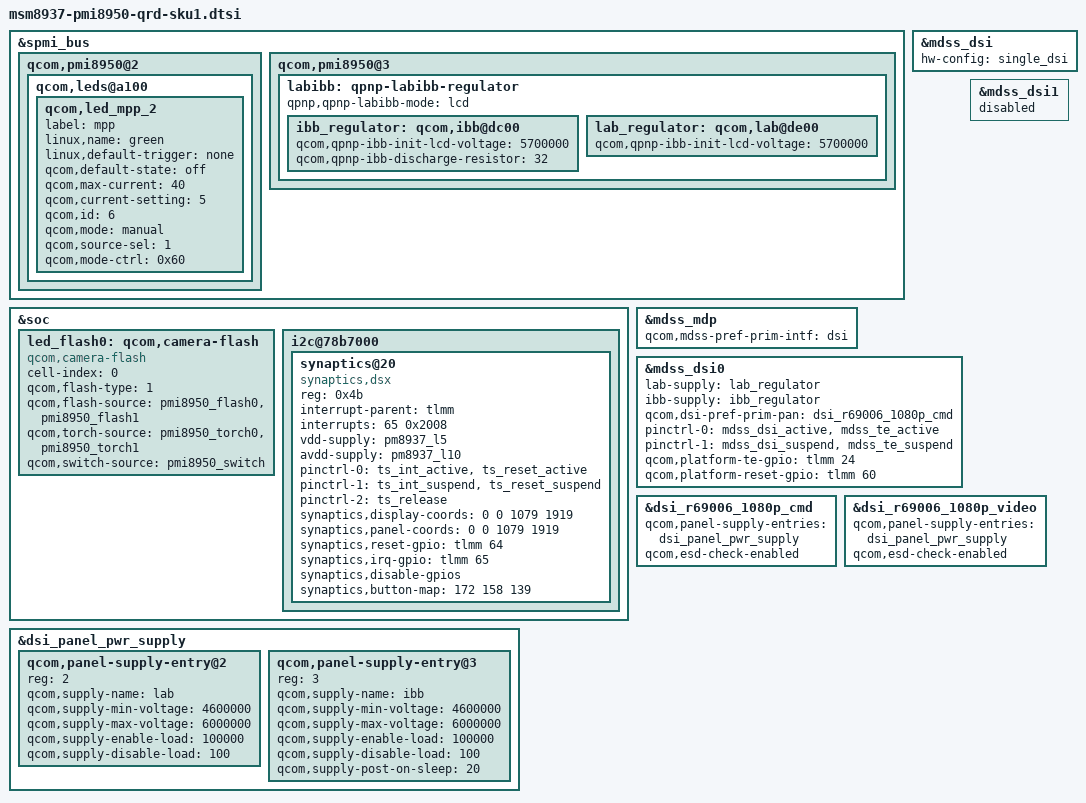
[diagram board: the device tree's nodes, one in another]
/*
 * Copyright (c) 2015, The Linux Foundation. All rights reserved.
 *
 * This program is free software; you can redistribute it and/or modify
 * it under the terms of the GNU General Public License version 2 and
 * only version 2 as published by the Free Software Foundation.
 *
 * This program is distributed in the hope that it will be useful,
 * but WITHOUT ANY WARRANTY; without even the implied warranty of
 * MERCHANTABILITY or FITNESS FOR A PARTICULAR PURPOSE.  See the
 * GNU General Public License for more details.
 */

#include "msm-pmi8950.dtsi"
#include "msm8937-qrd.dtsi"
#include "msm8937-mdss-panels.dtsi"

&spmi_bus {
	qcom,pmi8950@2 {
		qcom,leds@a100 {
			status = "okay";
			qcom,led_mpp_2 {
				label = "mpp";
				linux,name = "green";
				linux,default-trigger = "none";
				qcom,default-state = "off";
				qcom,max-current = <40>;
				qcom,current-setting = <5>;
				qcom,id = <6>;
				qcom,mode = "manual";
				qcom,source-sel = <1>;
				qcom,mode-ctrl = <0x60>;
			};
		};
	};
};

&soc {
	led_flash0: qcom,camera-flash {
		cell-index = <0>;
		compatible = "qcom,camera-flash";
		qcom,flash-type = <1>;
		qcom,flash-source = <&pmi8950_flash0 &pmi8950_flash1>;
		qcom,torch-source = <&pmi8950_torch0 &pmi8950_torch1>;
		qcom,switch-source = <&pmi8950_switch>;
	};

	i2c@78b7000 {
		status = "ok";
		synaptics@20 {
			compatible = "synaptics,dsx";
			reg = <0x4b>;
			interrupt-parent = <&tlmm>;
			interrupts = <65 0x2008>;
			vdd-supply = <&pm8937_l5>;
			avdd-supply = <&pm8937_l10>;
			pinctrl-names = "pmx_ts_active","pmx_ts_suspend",
				"pmx_ts_release";
			pinctrl-0 = <&ts_int_active &ts_reset_active>;
			pinctrl-1 = <&ts_int_suspend &ts_reset_suspend>;
			pinctrl-2 = <&ts_release>;
			synaptics,display-coords = <0 0 1079 1919>;
			synaptics,panel-coords = <0 0 1079 1919>;
			synaptics,reset-gpio = <&tlmm 64 0x00>;
			synaptics,irq-gpio = <&tlmm 65 0x2008>;
			synaptics,disable-gpios;
			synaptics,button-map = <172 158 139>;
		};
	};
};

&mdss_mdp {
	qcom,mdss-pref-prim-intf = "dsi";
};

&mdss_dsi {
	hw-config = "single_dsi";
};

&mdss_dsi0 {
	lab-supply = <&lab_regulator>;
	ibb-supply = <&ibb_regulator>;

	qcom,dsi-pref-prim-pan = <&dsi_r69006_1080p_cmd>;
	pinctrl-names = "mdss_default", "mdss_sleep";
	pinctrl-0 = <&mdss_dsi_active &mdss_te_active>;
	pinctrl-1 = <&mdss_dsi_suspend &mdss_te_suspend>;

	qcom,platform-te-gpio = <&tlmm 24 0>;
	qcom,platform-reset-gpio = <&tlmm 60 0>;
};

&mdss_dsi1 {
	status = "disabled";
};

&labibb {
	status = "ok";
	qpnp,qpnp-labibb-mode = "lcd";
};

&ibb_regulator {
	qcom,qpnp-ibb-discharge-resistor = <32>;
};

&dsi_panel_pwr_supply {
	qcom,panel-supply-entry@2 {
		reg = <2>;
		qcom,supply-name = "lab";
		qcom,supply-min-voltage = <4600000>;
		qcom,supply-max-voltage = <6000000>;
		qcom,supply-enable-load = <100000>;
		qcom,supply-disable-load = <100>;
	};

	qcom,panel-supply-entry@3 {
		reg = <3>;
		qcom,supply-name = "ibb";
		qcom,supply-min-voltage = <4600000>;
		qcom,supply-max-voltage = <6000000>;
		qcom,supply-enable-load = <100000>;
		qcom,supply-disable-load = <100>;
		qcom,supply-post-on-sleep = <20>;
	};
};

&dsi_r69006_1080p_cmd {
	qcom,panel-supply-entries = <&dsi_panel_pwr_supply>;
	qcom,esd-check-enabled;
};

&dsi_r69006_1080p_video {
	qcom,panel-supply-entries = <&dsi_panel_pwr_supply>;
	qcom,esd-check-enabled;
};

&spmi_bus {
	qcom,pmi8950@3 {
		labibb: qpnp-labibb-regulator {
			ibb_regulator: qcom,ibb@dc00 {
				/delete-property/
					qcom,qpnp-ibb-use-default-voltage;
				qcom,qpnp-ibb-init-lcd-voltage = <5700000>;
			};

			lab_regulator: qcom,lab@de00 {
				/delete-property/
					qcom,qpnp-ibb-use-default-voltage;
				qcom,qpnp-ibb-init-lcd-voltage = <5700000>;
			};
		};
	};
};
